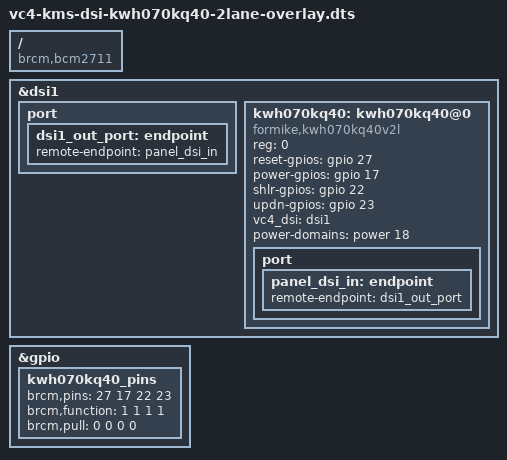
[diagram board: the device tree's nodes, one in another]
/dts-v1/;
/plugin/;

#include <dt-bindings/gpio/gpio.h>

/ {
    compatible = "brcm,bcm2711";

    fragment@0 {
        target=<&dsi1>;

        __overlay__ {
            status = "okay";
            #address-cells = <1>;
            #size-cells = <0>;
            port {
                dsi1_out_port: endpoint {
                    remote-endpoint = <&panel_dsi_in>;
                };
            };

            kwh070kq40: kwh070kq40@0 {
                compatible      = "formike,kwh070kq40v2l";
                status          = "okay";
                reg             = <0>;
                reset-gpios     = <&gpio 27 GPIO_ACTIVE_HIGH>;   // RESET
                power-gpios     = <&gpio 17 GPIO_ACTIVE_HIGH>;   // ENABLE
                shlr-gpios      = <&gpio 22 GPIO_ACTIVE_HIGH>;    // SHLDR
                updn-gpios      = <&gpio 23 GPIO_ACTIVE_HIGH>;    // UPDN
                vc4_dsi         = <&dsi1>;
                power-domains   = <&power 18>;
                port {
                    panel_dsi_in: endpoint {
                        remote-endpoint = <&dsi1_out_port>;
                    };
                };
            };
        };
    };

    fragment@1 {
        target = <&gpio>;
        __overlay__ {
            kwh070kq40_pins: kwh070kq40_pins {
                brcm,pins = <27 17 22 23>;
                brcm,function = <1 1 1 1>; // out
                brcm,pull = <0 0 0 0>; // off
            };
        };

    };

    __overrides__ {
        reset = <&kwh070kq40_pins>,"brcm,pins:27",
            <&kwh070kq40>,"reset-gpios:27";

        power = <&kwh070kq40_pins>,"brcm,pins:17",
            <&kwh070kq40>,"power-gpios:17";

        shlr = <&kwh070kq40_pins>,"brcm,pins:22",
            <&kwh070kq40>,"shlr-gpios:22";

        updn = <&kwh070kq40_pins>,"brcm,pins:23",
            <&kwh070kq40>,"updn-gpios:23";
    };
};
